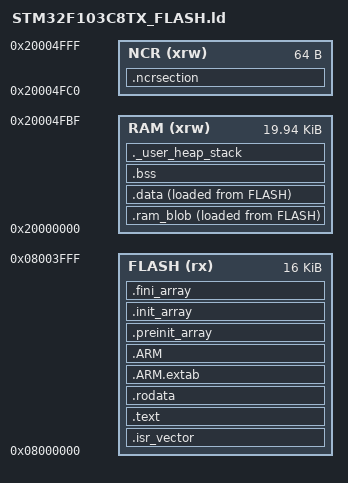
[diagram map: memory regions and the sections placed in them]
/*
******************************************************************************
**
** @file        : LinkerScript.ld
**
** @author      : Auto-generated by STM32CubeIDE
**
** @brief       : Linker script for STM32F103C8Tx Device from STM32F1 series
**                      64KBytes FLASH
**                      20KBytes RAM
**
**                Set heap size, stack size and stack location according
**                to application requirements.
**
**                Set memory bank area and size if external memory is used
**
**  Target      : STMicroelectronics STM32
**
**  Distribution: The file is distributed as is, without any warranty
**                of any kind.
**
******************************************************************************
** @attention
**
** Copyright (c) 2024 STMicroelectronics.
** All rights reserved.
**
** This software is licensed under terms that can be found in the LICENSE file
** in the root directory of this software component.
** If no LICENSE file comes with this software, it is provided AS-IS.
**
******************************************************************************
*/

/* Entry Point */
ENTRY(Reset_Handler)

/* Highest address of the user mode stack */
_estack = ORIGIN(RAM) + LENGTH(RAM); /* end of "RAM" Ram type memory */

_Min_Heap_Size = 0x100; /* required amount of heap */
_Min_Stack_Size = 0x100; /* required amount of stack */

/* Memories definition */
MEMORY
{
  	RAM (xrw) : ORIGIN = 0x20000000, LENGTH = 20416
  	FLASH    (rx)    : ORIGIN = 0x08000000,   LENGTH = 16K
	NCR (xrw) : ORIGIN = 0x20004FC0, LENGTH = 64
}
SECTIONS
{
  /* -------- special tiny RAM area -------- */
  .ncrsection :
  {
    *(.ncr)
  } > NCR

  /* -------- normal FBL in FLASH -------- */
  .isr_vector :
  {
    . = ALIGN(4);
    KEEP(*(.isr_vector))
    . = ALIGN(4);
  } > FLASH

  .text :
  {
    . = ALIGN(4);
    *(.text) *(.text*) *(.glue_7) *(.glue_7t) *(.eh_frame)
    KEEP (*(.init))
    KEEP (*(.fini))
    . = ALIGN(4);
    _etext = .;
  } > FLASH

  .rodata :
  {
    . = ALIGN(4);
    *(.rodata) *(.rodata*)
    . = ALIGN(4);
  } > FLASH

  .ARM.extab (READONLY) : { . = ALIGN(4); *(.ARM.extab* .gnu.linkonce.armextab.*) . = ALIGN(4); } > FLASH
  .ARM       (READONLY) : { . = ALIGN(4); __exidx_start = .; *(.ARM.exidx*) __exidx_end = .; . = ALIGN(4); } > FLASH
  .preinit_array (READONLY) : { . = ALIGN(4); PROVIDE_HIDDEN(__preinit_array_start = .); KEEP(*(.preinit_array*)) PROVIDE_HIDDEN(__preinit_array_end = .); . = ALIGN(4);} > FLASH
  .init_array    (READONLY) : { . = ALIGN(4); PROVIDE_HIDDEN(__init_array_start = .);  KEEP(*(SORT(.init_array.*))) KEEP(*(.init_array*))  PROVIDE_HIDDEN(__init_array_end = .);  . = ALIGN(4);} > FLASH
  .fini_array    (READONLY) : { . = ALIGN(4); PROVIDE_HIDDEN(__fini_array_start = .);  KEEP(*(SORT(.fini_array.*))) KEEP(*(.fini_array*))  PROVIDE_HIDDEN(__fini_array_end = .);  . = ALIGN(4);} > FLASH

  /* -------- RAM-EXEC blob: VMA in RAM, LMA in FLASH -------- */
  .ram_blob :
  {
    . = ALIGN(4);
    __ram_blob_vma_start = .;
    KEEP(*(.ram_blob_vectors))      /* must be first in blob */
    *(.ram_blob_text*)              /* code */
    *(.ram_blob_data*)              /* data */
    . = ALIGN(4);
    __ram_blob_vma_end = .;
  } > RAM AT> FLASH

  /* Copy helpers for the blob */
  __ram_blob_load_start = LOADADDR(.ram_blob);
  __ram_blob_load_end   = LOADADDR(.ram_blob) + SIZEOF(.ram_blob);

  /* -------- normal runtime data in RAM -------- */
  _sidata = LOADADDR(.data);
  .data :
  {
    . = ALIGN(4);
    _sdata = .;
    *(.data) *(.data*) *(.RamFunc) *(.RamFunc*)
    . = ALIGN(4);
    _edata = .;
  } > RAM AT> FLASH

  . = ALIGN(4);
  .bss :
  {
    _sbss = .; __bss_start__ = _sbss;
    *(.bss) *(.bss*) *(COMMON)
    . = ALIGN(4);
    _ebss = .; __bss_end__ = _ebss;
  } > RAM

  ._user_heap_stack :
  {
    . = ALIGN(8);
    PROVIDE(end = .); PROVIDE(_end = .);
    . = . + _Min_Heap_Size;
    . = . + _Min_Stack_Size;
    . = ALIGN(8);
  } > RAM

  /DISCARD/ : { libc.a(*); libm.a(*); libgcc.a(*) }
  .ARM.attributes 0 : { *(.ARM.attributes) }
}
